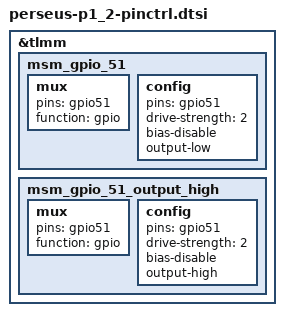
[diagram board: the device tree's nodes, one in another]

/* Copyright (c) 2016-2017, The Linux Foundation. All rights reserved.
 * Copyright (C) 2019 XiaoMi, Inc.
 *
 * This program is free software; you can redistribute it and/or modify
 * it under the terms of the GNU General Public License version 2 and
 * only version 2 as published by the Free Software Foundation.
 *
 * This program is distributed in the hope that it will be useful,
 * but WITHOUT ANY WARRANTY; without even the implied warranty of
 * MERCHANTABILITY or FITNESS FOR A PARTICULAR PURPOSE.  See the
 * GNU General Public License for more details.
 */
#include "perseus-p1-pinctrl.dtsi"


&tlmm {

	/* GPIO_51 : FP_RESET_N */
	msm_gpio_51: msm_gpio_51 {
		mux {
			 pins = "gpio51";
			 function = "gpio";
		};

		config {
			pins = "gpio51";
			drive-strength = <2>;
			bias-disable;
			output-low;
		};
	};

	/* GPIO_51 : FP_RESET_N, state device active*/
	msm_gpio_51_output_high: msm_gpio_51_output_high {
		mux {
			pins = "gpio51";
			function = "gpio";
		};

		config {
			pins = "gpio51";
			drive-strength = <2>;
			bias-disable;
			output-high;
		};
	};
};
